AUTOSAR XML (schema 4-0-3)
package /ServiceSwComponent_Det/PortInterface
  client server interface DETService: is-service=true, service-kind=DEVELOPMENT-ERROR-TRACER
    operation ReportError: possible-error=E_NOT_OK
      arg InstanceId: type=uint8, direction=IN, server-argument-impl-policy=USE-ARGUMENT-TYPE
      arg ApiId: type=uint8, direction=IN, server-argument-impl-policy=USE-ARGUMENT-TYPE
      arg ErrorId: type=uint8, direction=IN, server-argument-impl-policy=USE-ARGUMENT-TYPE
    error E_NOT_OK: error-code=1
package /ServiceSwComponent_Det/SwComponentType
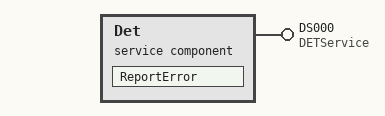
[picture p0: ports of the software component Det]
  service sw component type Det
    provide port DS000: server-com-spec{operation=ReportError, queue-length=1}, provided-interface=DETService
    behavior Det_InternalBehavior: port-api-option{enable-take-address=true, indirect-api=false, port-defined-argument-value{value=1, value-type=uint16}, port=DS000}
      operation invoked event OperationInvokedEvent_Det: start-on-event=ReportError, operation=DS000.ReportError
      runnable ReportError: arguments=[symbol=ModuleId, symbol=InstanceId, symbol=ApiId, symbol=ErrorId], can-be-invoked-concurrently=true, symbol=Det_ReportError
